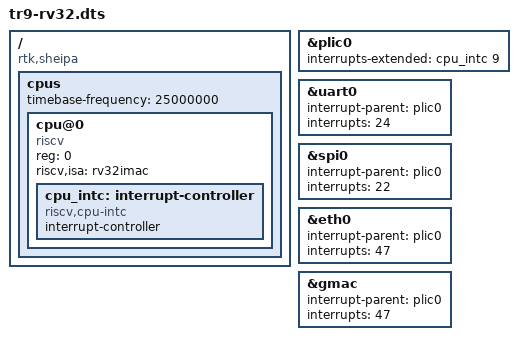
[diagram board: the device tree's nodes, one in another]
/*
 * Realtek Semiconductor Corp.
 *
 * Device Tree Structure
 *
 * Tony Wu (tonywu@realtek.com)
 */

/dts-v1/;

/ {
	compatible = "rtk,sheipa";
	#address-cells = <2>;
	#size-cells = <2>;

	cpus {
		#address-cells = <1>;
		#size-cells = <0>;
		timebase-frequency = <25000000>;

		cpu@0 {
			compatible = "riscv";
			device_type = "cpu";
			reg = <0>;
			riscv,isa = "rv32imac";
			status = "okay";

			cpu_intc: interrupt-controller {
				compatible = "riscv,cpu-intc";
				interrupt-controller;
				#interrupt-cells = <1>;
			};
		};
	};
};

#include "sheipa64.dtsi"

&plic0 {
	interrupts-extended = <&cpu_intc 9>;
};

&uart0 {
	interrupt-parent = <&plic0>;
	interrupts = <24>;
};

&spi0 {
	interrupt-parent = <&plic0>;
	interrupts = <22>;
};

&eth0 {
	interrupt-parent = <&plic0>;
	interrupts = <47>;
};

&gmac {
	interrupt-parent = <&plic0>;
	interrupts = <47>;
};
